# cslr_tpmgr register map
Vendor: Texas Instruments
Peripheral module from a debugger description file.
Registers are 32-bit, access not given, reset 0x444444 unless marked. A register's access mark holds for its fields unless they carry their own. Offsets are as the file gives them; lines under a group give offsets from that group; [hi:lo] are bit positions; {n}, {i} and the like mark numbered series; 'fields as' and 'values as' point back to an identical list; <NAME> marks a mode.

## TPMGR — TPMGR(Timer Pin Manager)
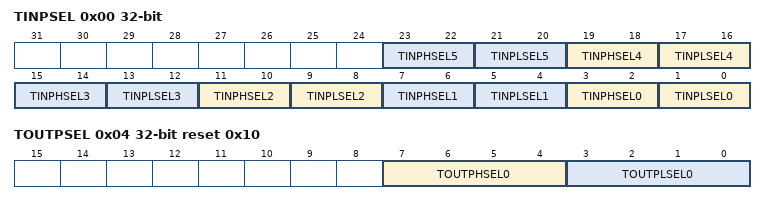
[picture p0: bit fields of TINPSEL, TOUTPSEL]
0x00 TINPSEL — TINPSEL(Timer Input Selection Register)
  [4n+3:4n+2] TINPHSEL{n} rw (n=0..5) — Input select for TIMER{n} high
  [4n+1:4n] TINPLSEL{n} rw (n=0..5) — Input select for TIMER{n} low
0x04 TOUTPSEL reset 0x10 — TOUTPSEL(Timer Output Selection Register )
  [7:4] TOUTPHSEL0 rw — Output select for TIMO1
  [3:0] TOUTPLSEL0 rw — Output select for TIMO0
